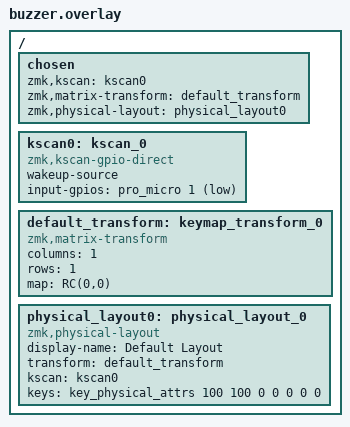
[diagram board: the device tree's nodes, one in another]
#include <dt-bindings/zmk/matrix_transform.h>
#include <physical_layouts.dtsi>

/ {
    chosen {
        zmk,kscan = <&kscan0>;
        zmk,matrix-transform = <&default_transform>;
        zmk,physical-layout = <&physical_layout0>;
    };

    kscan0: kscan_0 {
        compatible = "zmk,kscan-gpio-direct";
        wakeup-source;
        input-gpios = <&pro_micro 1 (GPIO_ACTIVE_LOW | GPIO_PULL_UP)>;
    };

    default_transform: keymap_transform_0 {
        compatible = "zmk,matrix-transform";
        columns = <1>;
        rows = <1>;
        map = <RC(0,0)>;
    };

    /* Required for ZMK Studio to draw the key */
    physical_layout0: physical_layout_0 {
        compatible = "zmk,physical-layout";
        display-name = "Default Layout";
        transform = <&default_transform>;
        kscan = <&kscan0>;
        keys = <&key_physical_attrs 100 100 0 0 0 0 0>;
    };
};
